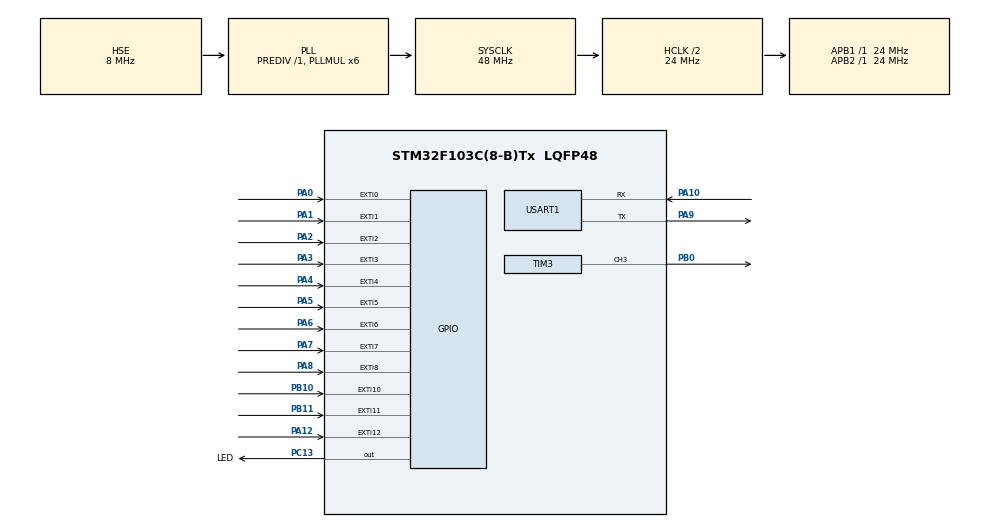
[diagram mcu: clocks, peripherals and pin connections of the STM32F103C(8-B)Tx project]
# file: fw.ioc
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FREERTOS.HEAP_NUMBER=1
FREERTOS.Tasks01=defaultTask,0,512,StartDefaultTask,Default,NULL,Dynamic,NULL,NULL
FREERTOS.configTOTAL_HEAP_SIZE=8192
Mcu.Family=STM32F1
Mcu.Name=STM32F103C(8-B)Tx
Mcu.Package=LQFP48
NVIC.EXTI0_IRQn=true\:5\:0\:false\:false\:true\:true\:true\:true
NVIC.EXTI15_10_IRQn=true\:5\:0\:false\:false\:true\:true\:true\:true
NVIC.EXTI1_IRQn=true\:5\:0\:false\:false\:true\:true\:true\:true
NVIC.EXTI2_IRQn=true\:5\:0\:false\:false\:true\:true\:true\:true
NVIC.EXTI3_IRQn=true\:5\:0\:false\:false\:true\:true\:true\:true
NVIC.EXTI4_IRQn=true\:5\:0\:false\:false\:true\:true\:true\:true
NVIC.EXTI9_5_IRQn=true\:5\:0\:false\:false\:true\:true\:true\:true
NVIC.PriorityGroup=NVIC_PRIORITYGROUP_4
NVIC.USART1_IRQn=true\:5\:0\:false\:false\:true\:true\:true\:true
PA0-WKUP.GPIO_ModeDefaultEXTI=GPIO_MODE_IT_RISING_FALLING
PA0-WKUP.GPIO_PuPd=GPIO_PULLUP
PA0-WKUP.Signal=GPXTI0
PA1.GPIO_ModeDefaultEXTI=GPIO_MODE_IT_RISING_FALLING
PA1.GPIO_PuPd=GPIO_PULLUP
PA1.Signal=GPXTI1
PA10.Mode=Asynchronous
PA10.Signal=USART1_RX
PA12.GPIO_ModeDefaultEXTI=GPIO_MODE_IT_RISING_FALLING
PA12.GPIO_PuPd=GPIO_PULLUP
PA12.Signal=GPXTI12
PA13.Mode=Serial_Wire
PA13.Signal=SYS_JTMS-SWDIO
PA14.Mode=Serial_Wire
PA14.Signal=SYS_JTCK-SWCLK
PA2.GPIO_ModeDefaultEXTI=GPIO_MODE_IT_RISING_FALLING
PA2.GPIO_PuPd=GPIO_PULLUP
PA2.Signal=GPXTI2
PA3.GPIO_ModeDefaultEXTI=GPIO_MODE_IT_RISING_FALLING
PA3.GPIO_PuPd=GPIO_PULLUP
PA3.Signal=GPXTI3
PA4.GPIO_ModeDefaultEXTI=GPIO_MODE_IT_RISING_FALLING
PA4.GPIO_PuPd=GPIO_PULLUP
PA4.Signal=GPXTI4
PA5.GPIO_ModeDefaultEXTI=GPIO_MODE_IT_RISING_FALLING
PA5.GPIO_PuPd=GPIO_PULLUP
PA5.Signal=GPXTI5
PA6.GPIO_ModeDefaultEXTI=GPIO_MODE_IT_RISING_FALLING
PA6.GPIO_PuPd=GPIO_PULLUP
PA6.Signal=GPXTI6
PA7.GPIO_ModeDefaultEXTI=GPIO_MODE_IT_RISING_FALLING
PA7.GPIO_PuPd=GPIO_PULLUP
PA7.Signal=GPXTI7
PA8.GPIO_ModeDefaultEXTI=GPIO_MODE_IT_RISING_FALLING
PA8.GPIO_PuPd=GPIO_PULLUP
PA8.Signal=GPXTI8
PA9.Mode=Asynchronous
PA9.Signal=USART1_TX
PB0.Signal=S_TIM3_CH3
PB10.GPIO_ModeDefaultEXTI=GPIO_MODE_IT_RISING_FALLING
PB10.Signal=GPXTI10
PB11.GPIO_ModeDefaultEXTI=GPIO_MODE_IT_RISING_FALLING
PB11.Signal=GPXTI11
PC13-TAMPER-RTC.GPIO_Label=LED
PC13-TAMPER-RTC.GPIO_Speed=GPIO_SPEED_FREQ_MEDIUM
PC13-TAMPER-RTC.Signal=GPIO_Output
PD0-OSC_IN.Mode=HSE-External-Oscillator
PD0-OSC_IN.Signal=RCC_OSC_IN
PD1-OSC_OUT.Mode=HSE-External-Oscillator
PD1-OSC_OUT.Signal=RCC_OSC_OUT
ProjectManager.HeapSize=0x200
ProjectManager.StackSize=0x400
ProjectManager.TargetToolchain=Makefile
RCC.AHBCLKDivider=RCC_SYSCLK_DIV2
RCC.AHBFreq_Value=24000000
RCC.APB1Freq_Value=24000000
RCC.APB1TimFreq_Value=24000000
RCC.APB2Freq_Value=24000000
RCC.APB2TimFreq_Value=24000000
RCC.HCLKFreq_Value=24000000
RCC.PLLMUL=RCC_PLL_MUL6
RCC.PLLSourceVirtual=RCC_PLLSOURCE_HSE
RCC.SYSCLKFreq_VALUE=48000000
RCC.SYSCLKSource=RCC_SYSCLKSOURCE_PLLCLK
RCC.USBFreq_Value=48000000
SH.S_TIM3_CH3.0=TIM3_CH3,PWM Generation3 CH3
TIM3.Channel-PWM\ Generation3\ CH3=TIM_CHANNEL_3
USART1.VirtualMode=VM_ASYNC
VP_FREERTOS_VS_ENABLE.Mode=Enabled
board=clicker

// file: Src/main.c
/**
  ******************************************************************************
  * File Name          : main.c
  * Description        : Main program body
  ******************************************************************************
  * This notice applies to any and all portions of this file
  * that are not between comment pairs USER CODE BEGIN and
  * USER CODE END. Other portions of this file, whether
  * inserted by the user or by software development tools
  * are owned by their respective copyright owners.
  *
  * Copyright (c) 2020 STMicroelectronics International N.V.
  * All rights reserved.
  *
  * Redistribution and use in source and binary forms, with or without
  * modification, are permitted, provided that the following conditions are met:
  *
  * 1. Redistribution of source code must retain the above copyright notice,
  *    this list of conditions and the following disclaimer.
  * 2. Redistributions in binary form must reproduce the above copyright notice,
  *    this list of conditions and the following disclaimer in the documentation
  *    and/or other materials provided with the distribution.
  * 3. Neither the name of STMicroelectronics nor the names of other
  *    contributors to this software may be used to endorse or promote products
  *    derived from this software without specific written permission.
  * 4. This software, including modifications and/or derivative works of this
  *    software, must execute solely and exclusively on microcontroller or
  *    microprocessor devices manufactured by or for STMicroelectronics.
  * 5. Redistribution and use of this software other than as permitted under
  *    this license is void and will automatically terminate your rights under
  *    this license.
  *
  * THIS SOFTWARE IS PROVIDED BY STMICROELECTRONICS AND CONTRIBUTORS "AS IS"
  * AND ANY EXPRESS, IMPLIED OR STATUTORY WARRANTIES, INCLUDING, BUT NOT
  * LIMITED TO, THE IMPLIED WARRANTIES OF MERCHANTABILITY, FITNESS FOR A
  * PARTICULAR PURPOSE AND NON-INFRINGEMENT OF THIRD PARTY INTELLECTUAL PROPERTY
  * RIGHTS ARE DISCLAIMED TO THE FULLEST EXTENT PERMITTED BY LAW. IN NO EVENT
  * SHALL STMICROELECTRONICS OR CONTRIBUTORS BE LIABLE FOR ANY DIRECT, INDIRECT,
  * INCIDENTAL, SPECIAL, EXEMPLARY, OR CONSEQUENTIAL DAMAGES (INCLUDING, BUT NOT
  * LIMITED TO, PROCUREMENT OF SUBSTITUTE GOODS OR SERVICES; LOSS OF USE, DATA,
  * OR PROFITS; OR BUSINESS INTERRUPTION) HOWEVER CAUSED AND ON ANY THEORY OF
  * LIABILITY, WHETHER IN CONTRACT, STRICT LIABILITY, OR TORT (INCLUDING
  * NEGLIGENCE OR OTHERWISE) ARISING IN ANY WAY OUT OF THE USE OF THIS SOFTWARE,
  * EVEN IF ADVISED OF THE POSSIBILITY OF SUCH DAMAGE.
  *
  ******************************************************************************
  */
#include "main.h"
#include "stm32f1xx_hal.h"
#include "cmsis_os.h"

TIM_HandleTypeDef htim3;

UART_HandleTypeDef huart1;

osThreadId defaultTaskHandle;

/* USER CODE BEGIN PV */
/* Private variables ---------------------------------------------------------*/

/* USER CODE END PV */

void SystemClock_Config(void);
static void MX_GPIO_Init(void);
static void MX_USART1_UART_Init(void);
static void MX_TIM3_Init(void);
void StartDefaultTask(void const * argument);
void HAL_TIM_MspPostInit(TIM_HandleTypeDef *htim);

/* USER CODE BEGIN PFP */
/* Private function prototypes -----------------------------------------------*/

void app();

/* USER CODE END PFP */

/* USER CODE BEGIN 0 */

/*
void _set_pwm(float value) {
    TIM_OC_InitTypeDef sConfigOC;

    sConfigOC.OCMode = TIM_OCMODE_PWM1;
    sConfigOC.Pulse = (uint16_t)(htim2.Init.Period * value);
    sConfigOC.OCPolarity = TIM_OCPOLARITY_HIGH;
    sConfigOC.OCFastMode = TIM_OCFAST_DISABLE;
    HAL_TIM_PWM_ConfigChannel(&htim2, &sConfigOC, TIM_CHANNEL_2);
    HAL_TIM_PWM_Start(&htim2, TIM_CHANNEL_2);
}
*/

/* USER CODE END 0 */

int main(void)
{

  /* MCU Configuration----------------------------------------------------------*/

  /* Reset of all peripherals, Initializes the Flash interface and the Systick. */
  HAL_Init();

  /* Configure the system clock */
  SystemClock_Config();

  /* Initialize all configured peripherals */
  MX_GPIO_Init();
  MX_USART1_UART_Init();
  MX_TIM3_Init();

  /* Create the thread(s) */
  /* definition and creation of defaultTask */
  osThreadDef(defaultTask, StartDefaultTask, osPriorityNormal, 0, 512);
  defaultTaskHandle = osThreadCreate(osThread(defaultTask), NULL);

  /* Start scheduler */
  osKernelStart();

  /* We should never get here as control is now taken by the scheduler */

  /* Infinite loop */

}

/** System Clock Configuration
*/
void SystemClock_Config(void)
{

  RCC_OscInitTypeDef RCC_OscInitStruct;
  RCC_ClkInitTypeDef RCC_ClkInitStruct;

    /**Initializes the CPU, AHB and APB busses clocks
    */
  RCC_OscInitStruct.OscillatorType = RCC_OSCILLATORTYPE_HSE;
  RCC_OscInitStruct.HSEState = RCC_HSE_ON;
  RCC_OscInitStruct.HSEPredivValue = RCC_HSE_PREDIV_DIV1;
  RCC_OscInitStruct.HSIState = RCC_HSI_ON;
  RCC_OscInitStruct.PLL.PLLState = RCC_PLL_ON;
  RCC_OscInitStruct.PLL.PLLSource = RCC_PLLSOURCE_HSE;
  RCC_OscInitStruct.PLL.PLLMUL = RCC_PLL_MUL6;
  if (HAL_RCC_OscConfig(&RCC_OscInitStruct) != HAL_OK)
  {
    _Error_Handler(__FILE__, __LINE__);
  }

    /**Initializes the CPU, AHB and APB busses clocks
    */
  RCC_ClkInitStruct.ClockType = RCC_CLOCKTYPE_HCLK|RCC_CLOCKTYPE_SYSCLK
                              |RCC_CLOCKTYPE_PCLK1|RCC_CLOCKTYPE_PCLK2;
  RCC_ClkInitStruct.SYSCLKSource = RCC_SYSCLKSOURCE_PLLCLK;
  RCC_ClkInitStruct.AHBCLKDivider = RCC_SYSCLK_DIV2;
  RCC_ClkInitStruct.APB1CLKDivider = RCC_HCLK_DIV1;
  RCC_ClkInitStruct.APB2CLKDivider = RCC_HCLK_DIV1;

  if (HAL_RCC_ClockConfig(&RCC_ClkInitStruct, FLASH_LATENCY_0) != HAL_OK)
  {
    _Error_Handler(__FILE__, __LINE__);
  }

    /**Configure the Systick interrupt time
    */
  HAL_SYSTICK_Config(HAL_RCC_GetHCLKFreq()/1000);

    /**Configure the Systick
    */
  HAL_SYSTICK_CLKSourceConfig(SYSTICK_CLKSOURCE_HCLK);

  /* SysTick_IRQn interrupt configuration */
  HAL_NVIC_SetPriority(SysTick_IRQn, 15, 0);
}

/* TIM3 init function */
static void MX_TIM3_Init(void)
{

  TIM_MasterConfigTypeDef sMasterConfig;
  TIM_OC_InitTypeDef sConfigOC;

  htim3.Instance = TIM3;
  htim3.Init.Prescaler = 0;
  htim3.Init.CounterMode = TIM_COUNTERMODE_UP;
  htim3.Init.Period = 0;
  htim3.Init.ClockDivision = TIM_CLOCKDIVISION_DIV1;
  if (HAL_TIM_PWM_Init(&htim3) != HAL_OK)
  {
    _Error_Handler(__FILE__, __LINE__);
  }

  sMasterConfig.MasterOutputTrigger = TIM_TRGO_RESET;
  sMasterConfig.MasterSlaveMode = TIM_MASTERSLAVEMODE_DISABLE;
  if (HAL_TIMEx_MasterConfigSynchronization(&htim3, &sMasterConfig) != HAL_OK)
  {
    _Error_Handler(__FILE__, __LINE__);
  }

  sConfigOC.OCMode = TIM_OCMODE_PWM1;
  sConfigOC.Pulse = 0;
  sConfigOC.OCPolarity = TIM_OCPOLARITY_HIGH;
  sConfigOC.OCFastMode = TIM_OCFAST_DISABLE;
  if (HAL_TIM_PWM_ConfigChannel(&htim3, &sConfigOC, TIM_CHANNEL_3) != HAL_OK)
  {
    _Error_Handler(__FILE__, __LINE__);
  }

  HAL_TIM_MspPostInit(&htim3);

}

/* USART1 init function */
static void MX_USART1_UART_Init(void)
{

  huart1.Instance = USART1;
  huart1.Init.BaudRate = 115200;
  huart1.Init.WordLength = UART_WORDLENGTH_8B;
  huart1.Init.StopBits = UART_STOPBITS_1;
  huart1.Init.Parity = UART_PARITY_NONE;
  huart1.Init.Mode = UART_MODE_TX_RX;
  huart1.Init.HwFlowCtl = UART_HWCONTROL_NONE;
  huart1.Init.OverSampling = UART_OVERSAMPLING_16;
  if (HAL_UART_Init(&huart1) != HAL_OK)
  {
    _Error_Handler(__FILE__, __LINE__);
  }

}

/** Configure pins as
        * Analog
        * Input
        * Output
        * EVENT_OUT
        * EXTI
*/
static void MX_GPIO_Init(void)
{

  GPIO_InitTypeDef GPIO_InitStruct;

  /* GPIO Ports Clock Enable */
  __HAL_RCC_GPIOC_CLK_ENABLE();
  __HAL_RCC_GPIOD_CLK_ENABLE();
  __HAL_RCC_GPIOA_CLK_ENABLE();
  __HAL_RCC_GPIOB_CLK_ENABLE();

  /*Configure GPIO pin Output Level */
  HAL_GPIO_WritePin(LED_GPIO_Port, LED_Pin, GPIO_PIN_RESET);

  /*Configure GPIO pin : LED_Pin */
  GPIO_InitStruct.Pin = LED_Pin;
  GPIO_InitStruct.Mode = GPIO_MODE_OUTPUT_PP;
  GPIO_InitStruct.Speed = GPIO_SPEED_FREQ_MEDIUM;
  HAL_GPIO_Init(LED_GPIO_Port, &GPIO_InitStruct);

  /*Configure GPIO pins : PA0 PA1 PA2 PA3
                           PA4 PA5 PA6 PA7
                           PA8 PA12 */
  GPIO_InitStruct.Pin = GPIO_PIN_0|GPIO_PIN_1|GPIO_PIN_2|GPIO_PIN_3
                          |GPIO_PIN_4|GPIO_PIN_5|GPIO_PIN_6|GPIO_PIN_7
                          |GPIO_PIN_8|GPIO_PIN_12;
  GPIO_InitStruct.Mode = GPIO_MODE_IT_RISING_FALLING;
  GPIO_InitStruct.Pull = GPIO_PULLUP;
  HAL_GPIO_Init(GPIOA, &GPIO_InitStruct);

  /*Configure GPIO pins : PB10 PB11 */
  GPIO_InitStruct.Pin = GPIO_PIN_10|GPIO_PIN_11;
  GPIO_InitStruct.Mode = GPIO_MODE_IT_RISING_FALLING;
  GPIO_InitStruct.Pull = GPIO_NOPULL;
  HAL_GPIO_Init(GPIOB, &GPIO_InitStruct);

  /* EXTI interrupt init*/
  HAL_NVIC_SetPriority(EXTI0_IRQn, 5, 0);
  HAL_NVIC_EnableIRQ(EXTI0_IRQn);

  HAL_NVIC_SetPriority(EXTI1_IRQn, 5, 0);
  HAL_NVIC_EnableIRQ(EXTI1_IRQn);

  HAL_NVIC_SetPriority(EXTI2_IRQn, 5, 0);
  HAL_NVIC_EnableIRQ(EXTI2_IRQn);

  HAL_NVIC_SetPriority(EXTI3_IRQn, 5, 0);
  HAL_NVIC_EnableIRQ(EXTI3_IRQn);

  HAL_NVIC_SetPriority(EXTI4_IRQn, 5, 0);
  HAL_NVIC_EnableIRQ(EXTI4_IRQn);

  HAL_NVIC_SetPriority(EXTI9_5_IRQn, 5, 0);
  HAL_NVIC_EnableIRQ(EXTI9_5_IRQn);

  HAL_NVIC_SetPriority(EXTI15_10_IRQn, 5, 0);
  HAL_NVIC_EnableIRQ(EXTI15_10_IRQn);

}

/* StartDefaultTask function */
void StartDefaultTask(void const * argument)
{

  /* USER CODE BEGIN 5 */
  app();

  /*
  gpio_init(GPIOB, GPIO_PIN_12, GPIO_MODE_OUTPUT_PP);
  gpio_init(GPIOB, GPIO_PIN_13, GPIO_MODE_OUTPUT_PP);
  gpio_init(GPIOB, GPIO_PIN_14, GPIO_MODE_INPUT);
  gpio_init(GPIOB, GPIO_PIN_15, GPIO_MODE_INPUT);
  */

  /*
  HAL_GPIO_WritePin(GPIOB, GPIO_PIN_12, GPIO_PIN_SET);
  HAL_GPIO_WritePin(GPIOB, GPIO_PIN_13, GPIO_PIN_RESET);
  osDelay(100);
  HAL_GPIO_WritePin(GPIOB, GPIO_PIN_12, GPIO_PIN_RESET);
  HAL_GPIO_WritePin(GPIOB, GPIO_PIN_13, GPIO_PIN_RESET);
  osDelay(100);
  HAL_GPIO_WritePin(GPIOB, GPIO_PIN_12, GPIO_PIN_RESET);
  HAL_GPIO_WritePin(GPIOB, GPIO_PIN_13, GPIO_PIN_SET);
  */

  /*
  float freqs[] = {0.1, 0.0, 0.3, 0.0, 0.3, 0.0, 0.3, 0.1};
  float freq = 0.35;

  size_t freq_index = 0;

  uint32_t delay_time = 50;

  while (1) {
    freq_index++;

    if(freq_index > (sizeof(freqs)/sizeof(freqs[0])) - 1) {
      freq_index = 0;
    }

    freq = freqs[freq_index];

    _set_pwm(freq);

    if(freq_index == 0) {
      HAL_GPIO_WritePin(LED_GPIO_Port, LED_Pin, GPIO_PIN_SET);
      osDelay(delay_time);
    } else if(freq_index == 1) {
      osDelay(delay_time);
      HAL_GPIO_WritePin(LED_GPIO_Port, LED_Pin, GPIO_PIN_RESET);
    } else {
      osDelay(delay_time);
    }
  }
  */

  /* USER CODE END 5 */
}

void _Error_Handler(char * file, int line)
{
  while(1)
  {
  }
}

/************************ (C) COPYRIGHT STMicroelectronics *****END OF FILE****/
